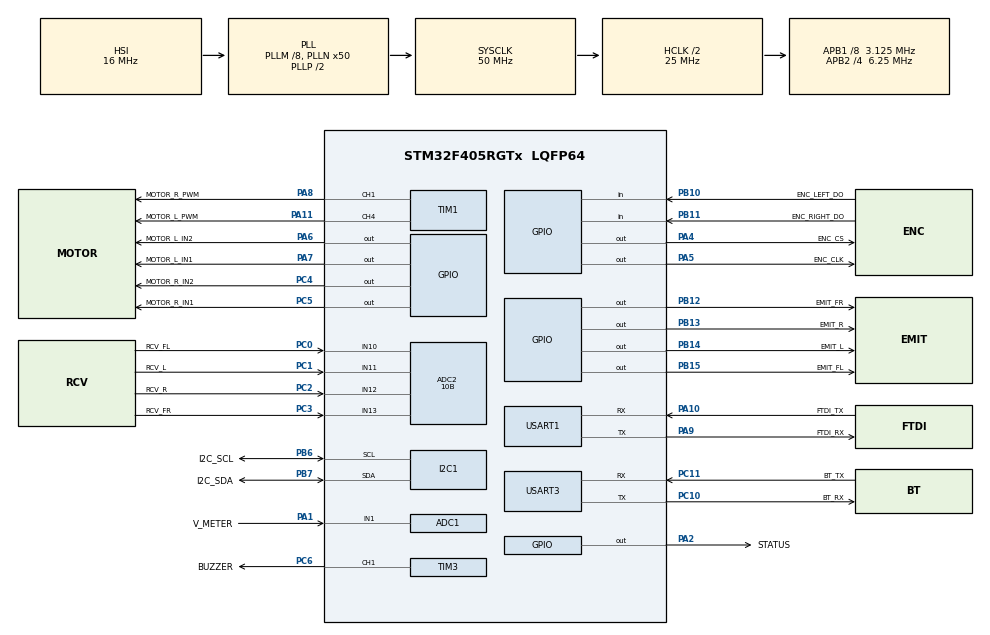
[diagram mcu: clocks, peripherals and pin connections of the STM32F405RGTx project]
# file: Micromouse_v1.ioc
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ADC1.Channel-0\#ChannelRegularConversion=ADC_CHANNEL_1
ADC1.Channel-IN1=ADC_CHANNEL_1
ADC1.ClockPrescaler=ADC_CLOCK_SYNC_PCLK_DIV8
ADC1.ContinuousConvMode=ENABLE
ADC1.DMAContinuousRequests=DISABLE
ADC1.DataAlign=ADC_DATAALIGN_RIGHT
ADC1.DiscontinuousConvMode=DISABLE
ADC1.EOCSelection=ADC_EOC_SEQ_CONV
ADC1.EnableAnalogWatchDog=false
ADC1.ExternalTrigConv=ADC_SOFTWARE_START
ADC1.ExternalTrigConvEdge=ADC_EXTERNALTRIGCONVEDGE_NONE
ADC1.InjNumberOfConversion=0
ADC1.NbrOfConversion=1
ADC1.NbrOfConversionFlag=1
ADC1.Rank-0\#ChannelRegularConversion=1
ADC1.Resolution=ADC_RESOLUTION_10B
ADC1.SamplingTime-0\#ChannelRegularConversion=ADC_SAMPLETIME_3CYCLES
ADC1.ScanConvMode=ENABLE
ADC1.master=1
ADC2.Channel-0\#ChannelRegularConversion=ADC_CHANNEL_10
ADC2.Channel-5\#ChannelRegularConversion=ADC_CHANNEL_11
ADC2.Channel-6\#ChannelRegularConversion=ADC_CHANNEL_12
ADC2.Channel-7\#ChannelRegularConversion=ADC_CHANNEL_13
ADC2.ClockPrescaler=ADC_CLOCK_SYNC_PCLK_DIV8
ADC2.ContinuousConvMode=ENABLE
ADC2.DMAContinuousRequests=DISABLE
ADC2.DataAlign=ADC_DATAALIGN_RIGHT
ADC2.DiscontinuousConvMode=DISABLE
ADC2.EOCSelection=ADC_EOC_SINGLE_CONV
ADC2.EnableAnalogWatchDog=false
ADC2.ExternalTrigConv=ADC_SOFTWARE_START
ADC2.ExternalTrigConvEdge=ADC_EXTERNALTRIGCONVEDGE_NONE
ADC2.InjNumberOfConversion=0
ADC2.NbrOfConversion=4
ADC2.NbrOfConversionFlag=1
ADC2.Rank-0\#ChannelRegularConversion=1
ADC2.Rank-5\#ChannelRegularConversion=2
ADC2.Rank-6\#ChannelRegularConversion=3
ADC2.Rank-7\#ChannelRegularConversion=4
ADC2.Resolution=ADC_RESOLUTION_10B
ADC2.SamplingTime-0\#ChannelRegularConversion=ADC_SAMPLETIME_112CYCLES
ADC2.SamplingTime-5\#ChannelRegularConversion=ADC_SAMPLETIME_112CYCLES
ADC2.SamplingTime-6\#ChannelRegularConversion=ADC_SAMPLETIME_112CYCLES
ADC2.SamplingTime-7\#ChannelRegularConversion=ADC_SAMPLETIME_112CYCLES
ADC2.ScanConvMode=ENABLE
Mcu.Family=STM32F4
Mcu.Name=STM32F405RGTx
Mcu.Package=LQFP64
NVIC.PriorityGroup=NVIC_PRIORITYGROUP_0
PA1.GPIO_Label=V_METER
PA1.Signal=ADCx_IN1
PA10.GPIO_Label=FTDI_TX
PA10.Mode=Multiprocessor_communication
PA10.Signal=USART1_RX
PA11.GPIO_Label=MOTOR_L_PWM
PA11.Signal=S_TIM1_CH4
PA2.GPIO_Label=STATUS
PA2.Signal=GPIO_Output
PA4.GPIO_Label=ENC_CS
PA4.Signal=GPIO_Output
PA5.GPIO_Label=ENC_CLK
PA5.Signal=GPIO_Output
PA6.GPIO_Label=MOTOR_L_IN2
PA6.Signal=GPIO_Output
PA7.GPIO_Label=MOTOR_L_IN1
PA7.Signal=GPIO_Output
PA8.GPIO_Label=MOTOR_R_PWM
PA8.Signal=S_TIM1_CH1
PA9.GPIO_Label=FTDI_RX
PA9.Mode=Multiprocessor_communication
PA9.Signal=USART1_TX
PB10.GPIO_Label=ENC_LEFT_DO
PB10.Signal=GPIO_Input
PB11.GPIO_Label=ENC_RIGHT_DO
PB11.Signal=GPIO_Input
PB12.GPIO_Label=EMIT_FR
PB12.Signal=GPIO_Output
PB13.GPIO_Label=EMIT_R
PB13.Signal=GPIO_Output
PB14.GPIO_Label=EMIT_L
PB14.Signal=GPIO_Output
PB15.GPIO_Label=EMIT_FL
PB15.Signal=GPIO_Output
PB6.GPIO_Label=I2C_SCL
PB6.Mode=I2C
PB6.Signal=I2C1_SCL
PB7.GPIO_Label=I2C_SDA
PB7.GPIO_Mode=GPIO_MODE_AF_OD
PB7.GPIO_Speed=GPIO_SPEED_FREQ_LOW
PB7.Mode=I2C
PB7.Signal=I2C1_SDA
PC0.GPIO_Label=RCV_FL
PC0.Signal=ADCx_IN10
PC1.GPIO_Label=RCV_L
PC1.Signal=ADCx_IN11
PC10.GPIO_Label=BT_RX
PC10.Mode=Multiprocessor_communication
PC10.Signal=USART3_TX
PC11.GPIO_Label=BT_TX
PC11.Mode=Multiprocessor_communication
PC11.Signal=USART3_RX
PC2.GPIO_Label=RCV_R
PC2.Signal=ADCx_IN12
PC3.GPIO_Label=RCV_FR
PC3.Signal=ADCx_IN13
PC4.GPIO_Label=MOTOR_R_IN2
PC4.Signal=GPIO_Output
PC5.GPIO_Label=MOTOR_R_IN1
PC5.Signal=GPIO_Output
PC6.GPIO_Label=BUZZER
PC6.Signal=S_TIM3_CH1
ProjectManager.HeapSize=0x200
ProjectManager.StackSize=0x400
ProjectManager.TargetToolchain=SW4STM32
RCC.48MHZClocksFreq_Value=25000000
RCC.AHBCLKDivider=RCC_SYSCLK_DIV2
RCC.AHBFreq_Value=25000000
RCC.APB1CLKDivider=RCC_HCLK_DIV8
RCC.APB1Freq_Value=3125000
RCC.APB1TimFreq_Value=6250000
RCC.APB2CLKDivider=RCC_HCLK_DIV4
RCC.APB2Freq_Value=6250000
RCC.APB2TimFreq_Value=12500000
RCC.CortexFreq_Value=25000000
RCC.HCLKFreq_Value=25000000
RCC.HSE_VALUE=25000000
RCC.HSI_VALUE=16000000
RCC.LSE_VALUE=32768
RCC.PLLM=8
RCC.PLLN=50
RCC.SYSCLKFreq_VALUE=50000000
RCC.SYSCLKSource=RCC_SYSCLKSOURCE_PLLCLK
RCC.VCOOutputFreq_Value=100000000
SH.ADCx_IN1.0=ADC1_IN1,IN1
SH.ADCx_IN10.0=ADC2_IN10,IN10
SH.ADCx_IN11.0=ADC2_IN11,IN11
SH.ADCx_IN12.0=ADC2_IN12,IN12
SH.ADCx_IN13.0=ADC2_IN13,IN13
SH.S_TIM1_CH1.0=TIM1_CH1,PWM Generation1 CH1
SH.S_TIM1_CH4.0=TIM1_CH4,PWM Generation4 CH4
SH.S_TIM3_CH1.0=TIM3_CH1,PWM Generation1 CH1
TIM1.Channel-PWM\ Generation1\ CH1=TIM_CHANNEL_1
TIM1.Channel-PWM\ Generation4\ CH4=TIM_CHANNEL_4
TIM3.Channel-PWM\ Generation1\ CH1=TIM_CHANNEL_1
USART1.VirtualMode=VM_ASYNC
USART3.VirtualMode=VM_ASYNC
board=Micromouse_v1

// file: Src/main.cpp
/**
  ******************************************************************************
  * File Name          : main.c
  * Description        : Main program body
  ******************************************************************************
  ** This notice applies to any and all portions of this file
  * that are not between comment pairs USER CODE BEGIN and
  * USER CODE END. Other portions of this file, whether
  * inserted by the user or by software development tools
  * are owned by their respective copyright owners.
  *
  * COPYRIGHT(c) 2018 STMicroelectronics
  *
  * Redistribution and use in source and binary forms, with or without modification,
  * are permitted provided that the following conditions are met:
  *   1. Redistributions of source code must retain the above copyright notice,
  *      this list of conditions and the following disclaimer.
  *   2. Redistributions in binary form must reproduce the above copyright notice,
  *      this list of conditions and the following disclaimer in the documentation
  *      and/or other materials provided with the distribution.
  *   3. Neither the name of STMicroelectronics nor the names of its contributors
  *      may be used to endorse or promote products derived from this software
  *      without specific prior written permission.
  *
  * THIS SOFTWARE IS PROVIDED BY THE COPYRIGHT HOLDERS AND CONTRIBUTORS "AS IS"
  * AND ANY EXPRESS OR IMPLIED WARRANTIES, INCLUDING, BUT NOT LIMITED TO, THE
  * IMPLIED WARRANTIES OF MERCHANTABILITY AND FITNESS FOR A PARTICULAR PURPOSE ARE
  * DISCLAIMED. IN NO EVENT SHALL THE COPYRIGHT HOLDER OR CONTRIBUTORS BE LIABLE
  * FOR ANY DIRECT, INDIRECT, INCIDENTAL, SPECIAL, EXEMPLARY, OR CONSEQUENTIAL
  * DAMAGES (INCLUDING, BUT NOT LIMITED TO, PROCUREMENT OF SUBSTITUTE GOODS OR
  * SERVICES; LOSS OF USE, DATA, OR PROFITS; OR BUSINESS INTERRUPTION) HOWEVER
  * CAUSED AND ON ANY THEORY OF LIABILITY, WHETHER IN CONTRACT, STRICT LIABILITY,
  * OR TORT (INCLUDING NEGLIGENCE OR OTHERWISE) ARISING IN ANY WAY OUT OF THE USE
  * OF THIS SOFTWARE, EVEN IF ADVISED OF THE POSSIBILITY OF SUCH DAMAGE.
  *
  ******************************************************************************
  */

#include "main.h"
#include "stm32f4xx_hal.h"

/* USER CODE BEGIN Includes */
#include "dwt_stm32_delay.h"
#include "Mouse.hpp"
/* USER CODE END Includes */

ADC_HandleTypeDef hadc1;
ADC_HandleTypeDef hadc2;

I2C_HandleTypeDef hi2c1;

TIM_HandleTypeDef htim1;
TIM_HandleTypeDef htim3;

UART_HandleTypeDef huart1;
UART_HandleTypeDef huart3;

/* USER CODE BEGIN PV */
/* Private variables ---------------------------------------------------------*/

/* USER CODE END PV */

void SystemClock_Config(void);
static void MX_GPIO_Init(void);
static void MX_ADC1_Init(void);
static void MX_I2C1_Init(void);
static void MX_TIM1_Init(void);
static void MX_TIM3_Init(void);
static void MX_USART1_UART_Init(void);
static void MX_USART3_UART_Init(void);
static void MX_ADC2_Init(void);

/* USER CODE BEGIN PFP */
/* Private function prototypes -----------------------------------------------*/
extern "C"
{
	void HAL_TIM_MspPostInit(TIM_HandleTypeDef *htim);
}
/* USER CODE END PFP */

int main(void)
{

  /* MCU Configuration----------------------------------------------------------*/

  /* Reset of all peripherals, Initializes the Flash interface and the Systick. */
  HAL_Init();

  /* USER CODE BEGIN Init */
  DWT_Delay_Init();
  /* USER CODE END Init */

  /* Configure the system clock */
  SystemClock_Config();

  /* Initialize all configured peripherals */
  MX_GPIO_Init();
  MX_ADC1_Init();
  MX_I2C1_Init();
  MX_TIM1_Init();
  MX_TIM3_Init();
  MX_USART1_UART_Init();
  MX_USART3_UART_Init();
  MX_ADC2_Init();

  /* USER CODE BEGIN 2 */
  Mouse::Instance()->Setup();
  /* USER CODE END 2 */

  /* Infinite loop */
  /* USER CODE BEGIN WHILE */
  while (1)
  {
	  Mouse::Instance()->Loop();
  /* USER CODE END WHILE */

  }

}

/** System Clock Configuration
*/
void SystemClock_Config(void)
{

  RCC_OscInitTypeDef RCC_OscInitStruct;
  RCC_ClkInitTypeDef RCC_ClkInitStruct;

    /**Configure the main internal regulator output voltage
    */
  __HAL_RCC_PWR_CLK_ENABLE();

  __HAL_PWR_VOLTAGESCALING_CONFIG(PWR_REGULATOR_VOLTAGE_SCALE1);

    /**Initializes the CPU, AHB and APB busses clocks
    */
  RCC_OscInitStruct.OscillatorType = RCC_OSCILLATORTYPE_HSI;
  RCC_OscInitStruct.HSIState = RCC_HSI_ON;
  RCC_OscInitStruct.HSICalibrationValue = 16;
  RCC_OscInitStruct.PLL.PLLState = RCC_PLL_ON;
  RCC_OscInitStruct.PLL.PLLSource = RCC_PLLSOURCE_HSI;
  RCC_OscInitStruct.PLL.PLLM = 8;
  RCC_OscInitStruct.PLL.PLLN = 50;
  RCC_OscInitStruct.PLL.PLLP = RCC_PLLP_DIV2;
  RCC_OscInitStruct.PLL.PLLQ = 4;
  if (HAL_RCC_OscConfig(&RCC_OscInitStruct) != HAL_OK)
  {
    _Error_Handler(__FILE__, __LINE__);
  }

    /**Initializes the CPU, AHB and APB busses clocks
    */
  RCC_ClkInitStruct.ClockType = RCC_CLOCKTYPE_HCLK|RCC_CLOCKTYPE_SYSCLK
                              |RCC_CLOCKTYPE_PCLK1|RCC_CLOCKTYPE_PCLK2;
  RCC_ClkInitStruct.SYSCLKSource = RCC_SYSCLKSOURCE_PLLCLK;
  RCC_ClkInitStruct.AHBCLKDivider = RCC_SYSCLK_DIV2;
  RCC_ClkInitStruct.APB1CLKDivider = RCC_HCLK_DIV8;
  RCC_ClkInitStruct.APB2CLKDivider = RCC_HCLK_DIV4;

  if (HAL_RCC_ClockConfig(&RCC_ClkInitStruct, FLASH_LATENCY_0) != HAL_OK)
  {
    _Error_Handler(__FILE__, __LINE__);
  }

    /**Configure the Systick interrupt time
    */
  HAL_SYSTICK_Config(HAL_RCC_GetHCLKFreq()/1000);

    /**Configure the Systick
    */
  HAL_SYSTICK_CLKSourceConfig(SYSTICK_CLKSOURCE_HCLK);

  /* SysTick_IRQn interrupt configuration */
  HAL_NVIC_SetPriority(SysTick_IRQn, 0, 0);
}

/* ADC1 init function */
static void MX_ADC1_Init(void)
{

  ADC_ChannelConfTypeDef sConfig;

    /**Configure the global features of the ADC (Clock, Resolution, Data Alignment and number of conversion)
    */
  hadc1.Instance = ADC1;
  hadc1.Init.ClockPrescaler = ADC_CLOCK_SYNC_PCLK_DIV8;
  hadc1.Init.Resolution = ADC_RESOLUTION_10B;
  hadc1.Init.ScanConvMode = ENABLE;
  hadc1.Init.ContinuousConvMode = ENABLE;
  hadc1.Init.DiscontinuousConvMode = DISABLE;
  hadc1.Init.ExternalTrigConvEdge = ADC_EXTERNALTRIGCONVEDGE_NONE;
  hadc1.Init.ExternalTrigConv = ADC_SOFTWARE_START;
  hadc1.Init.DataAlign = ADC_DATAALIGN_RIGHT;
  hadc1.Init.NbrOfConversion = 1;
  hadc1.Init.DMAContinuousRequests = DISABLE;
  hadc1.Init.EOCSelection = ADC_EOC_SEQ_CONV;
  if (HAL_ADC_Init(&hadc1) != HAL_OK)
  {
    _Error_Handler(__FILE__, __LINE__);
  }

    /**Configure for the selected ADC regular channel its corresponding rank in the sequencer and its sample time.
    */
  sConfig.Channel = ADC_CHANNEL_1;
  sConfig.Rank = 1;
  sConfig.SamplingTime = ADC_SAMPLETIME_3CYCLES;
  if (HAL_ADC_ConfigChannel(&hadc1, &sConfig) != HAL_OK)
  {
    _Error_Handler(__FILE__, __LINE__);
  }

}

/* ADC2 init function */
static void MX_ADC2_Init(void)
{

  ADC_ChannelConfTypeDef sConfig;

    /**Configure the global features of the ADC (Clock, Resolution, Data Alignment and number of conversion)
    */
  hadc2.Instance = ADC2;
  hadc2.Init.ClockPrescaler = ADC_CLOCK_SYNC_PCLK_DIV8;
  hadc2.Init.Resolution = ADC_RESOLUTION_10B;
  hadc2.Init.ScanConvMode = ENABLE;
  hadc2.Init.ContinuousConvMode = ENABLE;
  hadc2.Init.DiscontinuousConvMode = DISABLE;
  hadc2.Init.ExternalTrigConvEdge = ADC_EXTERNALTRIGCONVEDGE_NONE;
  hadc2.Init.ExternalTrigConv = ADC_SOFTWARE_START;
  hadc2.Init.DataAlign = ADC_DATAALIGN_RIGHT;
  hadc2.Init.NbrOfConversion = 4;
  hadc2.Init.DMAContinuousRequests = DISABLE;
  hadc2.Init.EOCSelection = ADC_EOC_SINGLE_CONV;
  if (HAL_ADC_Init(&hadc2) != HAL_OK)
  {
    _Error_Handler(__FILE__, __LINE__);
  }

    /**Configure for the selected ADC regular channel its corresponding rank in the sequencer and its sample time.
    */
  sConfig.Channel = ADC_CHANNEL_10;
  sConfig.Rank = 1;
  sConfig.SamplingTime = ADC_SAMPLETIME_112CYCLES;
  if (HAL_ADC_ConfigChannel(&hadc2, &sConfig) != HAL_OK)
  {
    _Error_Handler(__FILE__, __LINE__);
  }

    /**Configure for the selected ADC regular channel its corresponding rank in the sequencer and its sample time.
    */
  sConfig.Channel = ADC_CHANNEL_11;
  sConfig.Rank = 2;
  if (HAL_ADC_ConfigChannel(&hadc2, &sConfig) != HAL_OK)
  {
    _Error_Handler(__FILE__, __LINE__);
  }

    /**Configure for the selected ADC regular channel its corresponding rank in the sequencer and its sample time.
    */
  sConfig.Channel = ADC_CHANNEL_12;
  sConfig.Rank = 3;
  if (HAL_ADC_ConfigChannel(&hadc2, &sConfig) != HAL_OK)
  {
    _Error_Handler(__FILE__, __LINE__);
  }

    /**Configure for the selected ADC regular channel its corresponding rank in the sequencer and its sample time.
    */
  sConfig.Channel = ADC_CHANNEL_13;
  sConfig.Rank = 4;
  if (HAL_ADC_ConfigChannel(&hadc2, &sConfig) != HAL_OK)
  {
    _Error_Handler(__FILE__, __LINE__);
  }

}

/* I2C1 init function */
static void MX_I2C1_Init(void)
{

  hi2c1.Instance = I2C1;
  hi2c1.Init.ClockSpeed = 100000;
  hi2c1.Init.DutyCycle = I2C_DUTYCYCLE_2;
  hi2c1.Init.OwnAddress1 = 0;
  hi2c1.Init.AddressingMode = I2C_ADDRESSINGMODE_7BIT;
  hi2c1.Init.DualAddressMode = I2C_DUALADDRESS_DISABLE;
  hi2c1.Init.OwnAddress2 = 0;
  hi2c1.Init.GeneralCallMode = I2C_GENERALCALL_DISABLE;
  hi2c1.Init.NoStretchMode = I2C_NOSTRETCH_DISABLE;
  if (HAL_I2C_Init(&hi2c1) != HAL_OK)
  {
    _Error_Handler(__FILE__, __LINE__);
  }

}

/* TIM1 init function */
static void MX_TIM1_Init(void)
{

  TIM_MasterConfigTypeDef sMasterConfig;
  TIM_OC_InitTypeDef sConfigOC;
  TIM_BreakDeadTimeConfigTypeDef sBreakDeadTimeConfig;

  htim1.Instance = TIM1;
  htim1.Init.Prescaler = 0;
  htim1.Init.CounterMode = TIM_COUNTERMODE_UP;
  htim1.Init.Period = 0;
  htim1.Init.ClockDivision = TIM_CLOCKDIVISION_DIV1;
  htim1.Init.RepetitionCounter = 0;
  if (HAL_TIM_PWM_Init(&htim1) != HAL_OK)
  {
    _Error_Handler(__FILE__, __LINE__);
  }

  sMasterConfig.MasterOutputTrigger = TIM_TRGO_RESET;
  sMasterConfig.MasterSlaveMode = TIM_MASTERSLAVEMODE_DISABLE;
  if (HAL_TIMEx_MasterConfigSynchronization(&htim1, &sMasterConfig) != HAL_OK)
  {
    _Error_Handler(__FILE__, __LINE__);
  }

  sConfigOC.OCMode = TIM_OCMODE_PWM1;
  sConfigOC.Pulse = 0;
  sConfigOC.OCPolarity = TIM_OCPOLARITY_HIGH;
  sConfigOC.OCNPolarity = TIM_OCNPOLARITY_HIGH;
  sConfigOC.OCFastMode = TIM_OCFAST_DISABLE;
  sConfigOC.OCIdleState = TIM_OCIDLESTATE_RESET;
  sConfigOC.OCNIdleState = TIM_OCNIDLESTATE_RESET;
  if (HAL_TIM_PWM_ConfigChannel(&htim1, &sConfigOC, TIM_CHANNEL_1) != HAL_OK)
  {
    _Error_Handler(__FILE__, __LINE__);
  }

  if (HAL_TIM_PWM_ConfigChannel(&htim1, &sConfigOC, TIM_CHANNEL_4) != HAL_OK)
  {
    _Error_Handler(__FILE__, __LINE__);
  }

  sBreakDeadTimeConfig.OffStateRunMode = TIM_OSSR_DISABLE;
  sBreakDeadTimeConfig.OffStateIDLEMode = TIM_OSSI_DISABLE;
  sBreakDeadTimeConfig.LockLevel = TIM_LOCKLEVEL_OFF;
  sBreakDeadTimeConfig.DeadTime = 0;
  sBreakDeadTimeConfig.BreakState = TIM_BREAK_DISABLE;
  sBreakDeadTimeConfig.BreakPolarity = TIM_BREAKPOLARITY_HIGH;
  sBreakDeadTimeConfig.AutomaticOutput = TIM_AUTOMATICOUTPUT_DISABLE;
  if (HAL_TIMEx_ConfigBreakDeadTime(&htim1, &sBreakDeadTimeConfig) != HAL_OK)
  {
    _Error_Handler(__FILE__, __LINE__);
  }

  HAL_TIM_MspPostInit(&htim1);

}

/* TIM3 init function */
static void MX_TIM3_Init(void)
{

  TIM_MasterConfigTypeDef sMasterConfig;
  TIM_OC_InitTypeDef sConfigOC;

  htim3.Instance = TIM3;
  htim3.Init.Prescaler = 0;
  htim3.Init.CounterMode = TIM_COUNTERMODE_UP;
  htim3.Init.Period = 0;
  htim3.Init.ClockDivision = TIM_CLOCKDIVISION_DIV1;
  if (HAL_TIM_PWM_Init(&htim3) != HAL_OK)
  {
    _Error_Handler(__FILE__, __LINE__);
  }

  sMasterConfig.MasterOutputTrigger = TIM_TRGO_RESET;
  sMasterConfig.MasterSlaveMode = TIM_MASTERSLAVEMODE_DISABLE;
  if (HAL_TIMEx_MasterConfigSynchronization(&htim3, &sMasterConfig) != HAL_OK)
  {
    _Error_Handler(__FILE__, __LINE__);
  }

  sConfigOC.OCMode = TIM_OCMODE_PWM1;
  sConfigOC.Pulse = 0;
  sConfigOC.OCPolarity = TIM_OCPOLARITY_HIGH;
  sConfigOC.OCFastMode = TIM_OCFAST_DISABLE;
  if (HAL_TIM_PWM_ConfigChannel(&htim3, &sConfigOC, TIM_CHANNEL_1) != HAL_OK)
  {
    _Error_Handler(__FILE__, __LINE__);
  }

  HAL_TIM_MspPostInit(&htim3);

}

/* USART1 init function */
static void MX_USART1_UART_Init(void)
{

  huart1.Instance = USART1;
  huart1.Init.BaudRate = 115200;
  huart1.Init.WordLength = UART_WORDLENGTH_8B;
  huart1.Init.StopBits = UART_STOPBITS_1;
  huart1.Init.Parity = UART_PARITY_NONE;
  huart1.Init.Mode = UART_MODE_TX_RX;
  huart1.Init.HwFlowCtl = UART_HWCONTROL_NONE;
  huart1.Init.OverSampling = UART_OVERSAMPLING_16;
  if (HAL_MultiProcessor_Init(&huart1, 0, UART_WAKEUPMETHOD_IDLELINE) != HAL_OK)
  {
    _Error_Handler(__FILE__, __LINE__);
  }

}

/* USART3 init function */
static void MX_USART3_UART_Init(void)
{

  huart3.Instance = USART3;
  huart3.Init.BaudRate = 115200;
  huart3.Init.WordLength = UART_WORDLENGTH_8B;
  huart3.Init.StopBits = UART_STOPBITS_1;
  huart3.Init.Parity = UART_PARITY_NONE;
  huart3.Init.Mode = UART_MODE_TX_RX;
  huart3.Init.HwFlowCtl = UART_HWCONTROL_NONE;
  huart3.Init.OverSampling = UART_OVERSAMPLING_16;
  if (HAL_MultiProcessor_Init(&huart3, 0, UART_WAKEUPMETHOD_IDLELINE) != HAL_OK)
  {
    _Error_Handler(__FILE__, __LINE__);
  }

}

/** Configure pins as
        * Analog
        * Input
        * Output
        * EVENT_OUT
        * EXTI
*/
static void MX_GPIO_Init(void)
{

  GPIO_InitTypeDef GPIO_InitStruct;

  /* GPIO Ports Clock Enable */
  __HAL_RCC_GPIOC_CLK_ENABLE();
  __HAL_RCC_GPIOA_CLK_ENABLE();
  __HAL_RCC_GPIOB_CLK_ENABLE();

  /*Configure GPIO pin Output Level */
  HAL_GPIO_WritePin(GPIOA, STATUS_Pin|ENC_CS_Pin|ENC_CLK_Pin|MOTOR_L_IN2_Pin
                          |MOTOR_L_IN1_Pin, GPIO_PIN_RESET);

  /*Configure GPIO pin Output Level */
  HAL_GPIO_WritePin(GPIOC, MOTOR_R_IN2_Pin|MOTOR_R_IN1_Pin, GPIO_PIN_RESET);

  /*Configure GPIO pin Output Level */
  HAL_GPIO_WritePin(GPIOB, EMIT_FR_Pin|EMIT_R_Pin|EMIT_L_Pin|EMIT_FL_Pin, GPIO_PIN_RESET);

  /*Configure GPIO pins : STATUS_Pin ENC_CS_Pin ENC_CLK_Pin MOTOR_L_IN2_Pin
                           MOTOR_L_IN1_Pin */
  GPIO_InitStruct.Pin = STATUS_Pin|ENC_CS_Pin|ENC_CLK_Pin|MOTOR_L_IN2_Pin
                          |MOTOR_L_IN1_Pin;
  GPIO_InitStruct.Mode = GPIO_MODE_OUTPUT_PP;
  GPIO_InitStruct.Pull = GPIO_NOPULL;
  GPIO_InitStruct.Speed = GPIO_SPEED_FREQ_LOW;
  HAL_GPIO_Init(GPIOA, &GPIO_InitStruct);

  /*Configure GPIO pins : MOTOR_R_IN2_Pin MOTOR_R_IN1_Pin */
  GPIO_InitStruct.Pin = MOTOR_R_IN2_Pin|MOTOR_R_IN1_Pin;
  GPIO_InitStruct.Mode = GPIO_MODE_OUTPUT_PP;
  GPIO_InitStruct.Pull = GPIO_NOPULL;
  GPIO_InitStruct.Speed = GPIO_SPEED_FREQ_LOW;
  HAL_GPIO_Init(GPIOC, &GPIO_InitStruct);

  /*Configure GPIO pins : ENC_LEFT_DO_Pin ENC_RIGHT_DO_Pin */
  GPIO_InitStruct.Pin = ENC_LEFT_DO_Pin|ENC_RIGHT_DO_Pin;
  GPIO_InitStruct.Mode = GPIO_MODE_INPUT;
  GPIO_InitStruct.Pull = GPIO_NOPULL;
  HAL_GPIO_Init(GPIOB, &GPIO_InitStruct);

  /*Configure GPIO pins : EMIT_FR_Pin EMIT_R_Pin EMIT_L_Pin EMIT_FL_Pin */
  GPIO_InitStruct.Pin = EMIT_FR_Pin|EMIT_R_Pin|EMIT_L_Pin|EMIT_FL_Pin;
  GPIO_InitStruct.Mode = GPIO_MODE_OUTPUT_PP;
  GPIO_InitStruct.Pull = GPIO_NOPULL;
  GPIO_InitStruct.Speed = GPIO_SPEED_FREQ_LOW;
  HAL_GPIO_Init(GPIOB, &GPIO_InitStruct);

}

void _Error_Handler(char * file, int line)
{
  while(1)
  {
  }
}

/************************ (C) COPYRIGHT STMicroelectronics *****END OF FILE****/
